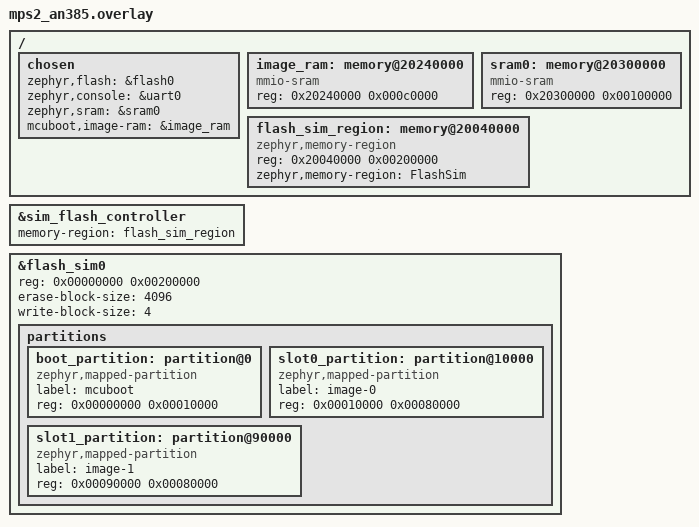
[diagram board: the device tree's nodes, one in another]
/*
 * Copyright (c) 2026 The Zephyr Project Contributors
 *
 * SPDX-License-Identifier: Apache-2.0
 */

/delete-node/ &sram0;
/delete-node/ &{/sim_flash_controller/flash_sim@0/partitions};

/ {
	chosen {
		zephyr,flash = &flash0;
		zephyr,console = &uart0;
		zephyr,sram = &sram0;
		mcuboot,image-ram = &image_ram;

		/delete-property/ zephyr,code-partition;
	};

	image_ram: memory@20240000 {
		compatible = "mmio-sram";
		reg = <0x20240000 0x000c0000>;
	};

	sram0: memory@20300000 {
		compatible = "mmio-sram";
		reg = <0x20300000 0x00100000>;
	};

	flash_sim_region: memory@20040000 {
		compatible = "zephyr,memory-region", "mmio-sram";
		reg = <0x20040000 0x00200000>;
		ranges = <0x0 0x20040000 0x00200000>;
		zephyr,memory-region = "FlashSim";
		status = "okay";
		#address-cells = <1>;
		#size-cells = <1>;
	};
};

&sim_flash_controller {
	memory-region = <&flash_sim_region>;
};

&flash_sim0 {
	reg = <0x00000000 0x00200000>;
	erase-block-size = <4096>;
	write-block-size = <4>;
	#address-cells = <1>;
	#size-cells = <1>;
	ranges = <0x0 0x0 0x00200000>;

	partitions {
		ranges;
		#address-cells = <1>;
		#size-cells = <1>;

		boot_partition: partition@0 {
			compatible = "zephyr,mapped-partition";
			label = "mcuboot";
			reg = <0x00000000 0x00010000>;
		};

		slot0_partition: partition@10000 {
			compatible = "zephyr,mapped-partition";
			label = "image-0";
			reg = <0x00010000 0x00080000>;
		};

		slot1_partition: partition@90000 {
			compatible = "zephyr,mapped-partition";
			label = "image-1";
			reg = <0x00090000 0x00080000>;
		};
	};
};
